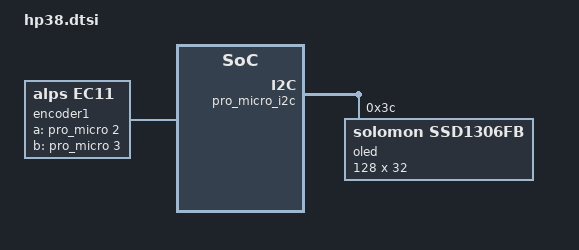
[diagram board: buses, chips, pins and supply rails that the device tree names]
/*
 * Copyright (c) 2020 Pete Johanson
 *
 * SPDX-License-Identifier: MIT
 */

#include <dt-bindings/zmk/matrix_transform.h>

/ {
    encoder1: encoder {
        compatible = "alps,ec11";
        a-gpios = <&pro_micro 2 (GPIO_ACTIVE_HIGH | GPIO_PULL_UP)>;
        b-gpios = <&pro_micro 3 (GPIO_ACTIVE_HIGH | GPIO_PULL_UP)>;
        steps = <80>;
    };

    sensors: sensors {
        compatible = "zmk,keymap-sensors";
        sensors = <&encoder1>;
        triggers-per-rotation = <20>;
    };
};

&pro_micro_i2c {
    status = "okay";

    oled: ssd1306@3c {
        compatible = "solomon,ssd1306fb";
        reg = <0x3c>;
        width = <128>;
        height = <32>;
        segment-offset = <0>;
        page-offset = <0>;
        display-offset = <0>;
        multiplex-ratio = <31>;
        segment-remap;
        com-invdir;
        com-sequential;
        prechargep = <0x22>;
    };
};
